# CY8C5888LTI_LP097 register map
File version: 0.1
CY8C58LP
Registers are 8-bit, read-write, no defined reset value unless marked. A register's access mark holds for its fields unless they carry their own. Offsets are from the block's base; lines under a group give offsets from that group; [hi:lo] are bit positions; {n}, {i} and the like mark numbered series; 'fields as' and 'values as' point back to an identical list; <NAME> marks a mode.

## Memory map
0x00000000 I2C
0x00000000 ADC_Flow — SAR ADC
0x00000000 RTC
0x00000000 UART
0x00000000 PWM_PERISTALTISK_2
0x00000000 ADC_PH — SAR ADC
0x00000000 PWM_PERISTALTISK_1
0x00000000 DS18x8_TimerDelay
0x00000000 DS18x8_ControlReg_SEL
0x00000000 DS18x8_ControlReg_DRV
0x00000000 DS18x8_StatusReg_BUS
0x00000000 DS18x8_Trigger

## ADC_Flow — SAR ADC
Base 0x00000000
0x40004616 SAR_TR0 — SAR trim register
{0x40005908+i} SAR_CSR{i} (i=0..6) — SAR status and control register {i}
0x40005B28 SAR_SW0 — SAR Analog Routing Register 0
{0x40005B28+i} SAR_SW{i} (i=2..4) — SAR Analog Routing Register {i}
0x40005B2E SAR_SW6 — SAR Analog Routing Register 6
0x40005B2F SAR_CLK — SAR Clock Selection Register
0x40005BA2 SAR_WRK 16-bit — SAR working register

## RTC
Base 0x00000000
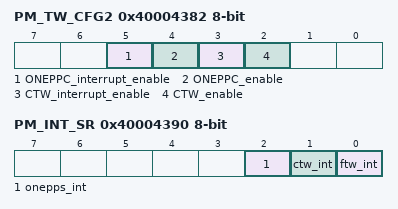
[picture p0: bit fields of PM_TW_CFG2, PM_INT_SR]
0x40004382 PM_TW_CFG2 — Power timers enable and interrupt enable configuration register
  [5] ONEPPC_interrupt_enable — When set and one pulse-per-second is enabled, an interrupt is issued when the pulse occurs
    1=Enabled (The ONEPPC interrupt is issued. Only if ONEPPC is enabled.); 0=Disabled (No ONEPPC interrupt is issued.)
  [4] ONEPPC_enable
    1=Enabled (The ONEPPC is enabled.); 0=Disabled (The ONEPPC is disabled.)
  [3] CTW_interrupt_enable — An interrupt issue when the CTW reaches the selected interval
    1=Enabled (The CTW interrupt is issued. Only if CTW is enabled.); 0=Disabled (No CTW interrupt is issued.)
  [2] CTW_enable
    1=Enabled (The CTW is enabled.); 0=Disabled (The CTW is disabled.)
0x40004390 PM_INT_SR — Power Manager Interrupt Status Register
  [2] onepps_int — When set, a onepps event has occured.
  [1] ctw_int — When set, a limited active ready event has occured
  [0] ftw_int — When set, a fast timewheel event has occured

## UART
Base 0x00000000
0x40006449 TX_UART_TX_DATA — TX Data Register
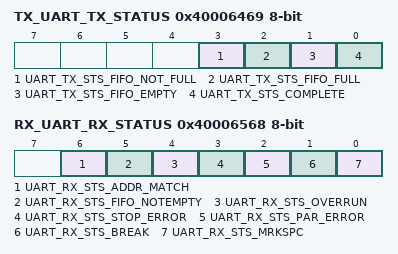
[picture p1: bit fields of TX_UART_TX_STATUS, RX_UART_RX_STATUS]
0x40006469 TX_UART_TX_STATUS — TX status register
  [3] UART_TX_STS_FIFO_NOT_FULL ro, [2] UART_TX_STS_FIFO_FULL ro, [1] UART_TX_STS_FIFO_EMPTY ro, [0] UART_TX_STS_COMPLETE ro
0x40006528 RX_UART_RX_ADDRESS1 — RX Address1 Register
0x40006538 RX_UART_RX_ADDRESS2 — RX Address2 Register
0x40006548 RX_UART_RX_DATA — RX Data Register
0x40006568 RX_UART_RX_STATUS — RX status register
  [6] UART_RX_STS_ADDR_MATCH ro, [5] UART_RX_STS_FIFO_NOTEMPTY ro, [4] UART_RX_STS_OVERRUN ro, [3] UART_RX_STS_STOP_ERROR ro, [2] UART_RX_STS_PAR_ERROR ro, [1] UART_RX_STS_BREAK ro, [0] UART_RX_STS_MRKSPC ro

## PWM_PERISTALTISK_2
Base 0x00000000
0x40006423 PWM_PERISTALTISK_2_COMPARE_Reg_ — UDB.D0 - Assigned Compare Value
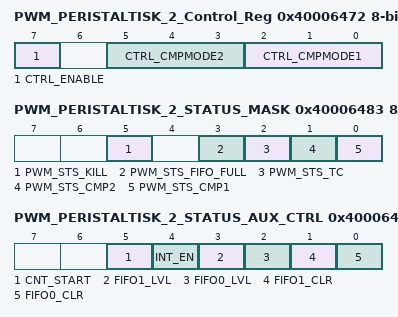
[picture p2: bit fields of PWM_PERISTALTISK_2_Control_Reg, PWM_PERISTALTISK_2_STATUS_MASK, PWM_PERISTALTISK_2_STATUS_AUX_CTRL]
0x40006472 PWM_PERISTALTISK_2_Control_Reg — UDB Control Register - Assigned Control Register Value
  [7] CTRL_ENABLE — Enable the PWM
  [5:3] CTRL_CMPMODE2 — Compare mode 2
  [2:0] CTRL_CMPMODE1 — Compare mode 1
0x40006483 PWM_PERISTALTISK_2_STATUS_MASK — UDB Status bits Interrupt Mask Enable Register
  [5] PWM_STS_KILL ro — Enables the Interrupt on Kill
  [3] PWM_STS_FIFO_FULL ro — FIFO Full Status Mask
  [2] PWM_STS_TC ro — Enables the Interrupt on Terminal Count
  [1] PWM_STS_CMP2 ro — Enables the Interrupt on Compare 2
  [0] PWM_STS_CMP1 ro — Enables the Interrupt on Compare 1
0x40006493 PWM_PERISTALTISK_2_STATUS_AUX_CTRL — UDB Auxilliary Control Register
  [5] CNT_START — FIFO0 clear
    0=E_CNT_START0 (Disable counter); 1=E_CNT_START1 (Enable counter)
  [4] INT_EN
    0=E_INT_EN0 (Interrupt disabled); 1=E_INT_EN1 (Interrupt enabled)
  [3] FIFO1_LVL — FIFO level
    0=E_FIFO_LVL_0 (FIFO LVL: input mode: FIFO not full; output mode: FIFO not empty); 1=E_FIFO_LVL_1 (FIFO LVL: input mode: FIFO at least 1/2 empty; output mode: FIFO at least 1/2 full)
  [2] FIFO0_LVL — FIFO level
    values as FIFO1_LVL
  [1] FIFO1_CLR — FIFO1 clear
    0=E_FIFO_CLR_0 (Normal FIFO operation); 1=E_FIFO_CLR_1 (Clear FIFO state)
  [0] FIFO0_CLR — FIFO0 clear
    values as FIFO1_CLR
